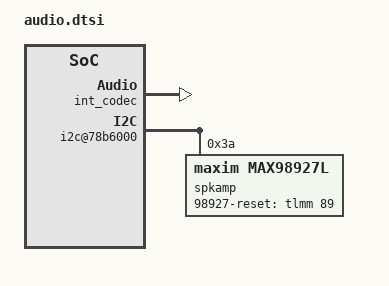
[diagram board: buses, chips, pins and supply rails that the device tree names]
/* msm-audio */
&soc {
	int_codec: sound {
		status = "ok";
		qcom,msm-hs-micbias-type = "internal";
		qcom,audio-routing =
			"RX_BIAS", "MCLK",
			"SPK_RX_BIAS", "MCLK",
			"INT_LDO_H", "MCLK",
			"MIC BIAS External", "Handset Mic",
			"MIC BIAS Internal2", "Headset Mic",
			"MIC BIAS External", "Secondary Mic",
			"AMIC1", "MIC BIAS External",
			"AMIC2", "MIC BIAS Internal2",
			"AMIC3", "MIC BIAS External";
		/delete-property/qcom,hdmi-dba-codec-rx;
	};
	i2c@78b6000 {
		status = "okay";
		spkamp@3a {/* max98927 smartpa device*/
			compatible = "maxim,max98927L";
			status = "okay";
			reg = <0x3a>;
			mono_stereo_mode = <0>;
			interleave_mode = <0>;
			vmon-l-slot = <1>;
			imon-l-slot = <1>;
			vmon-r-slot = <1>;
			imon-r-slot = <1>;
			maxim,98927-reset-gpio = <&tlmm 89 0>;
		};
	};
};

/* msm8953-audio */
&int_codec {
	/delete-property/msm-vdd-wsa-switch-supply;
	/delete-property/qcom,msm-vdd-wsa-switch-voltage;
	/delete-property/qcom,msm-vdd-wsa-switch-current;
};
